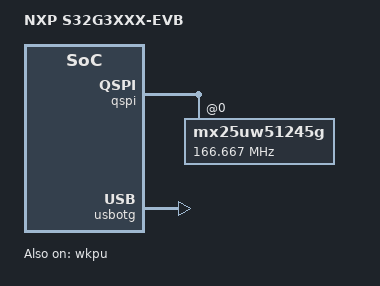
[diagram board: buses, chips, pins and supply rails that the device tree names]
// SPDX-License-Identifier: (GPL-2.0+ OR BSD-3-Clause)
/*
 * Copyright 2021-2023 NXP
 */

/dts-v1/;
#include "s32g.dtsi"
#include "s32g3.dtsi"
#include "s32gxxxa-evb.dtsi"

/ {
	model = "NXP S32G3XXX-EVB";
};

&qspi {
	mx25uw51245g@0 {
		spi-max-frequency = <166666666>;
	};
};

&usbotg {
	status = "okay";
};

&wkpu {
	status = "okay";
};
